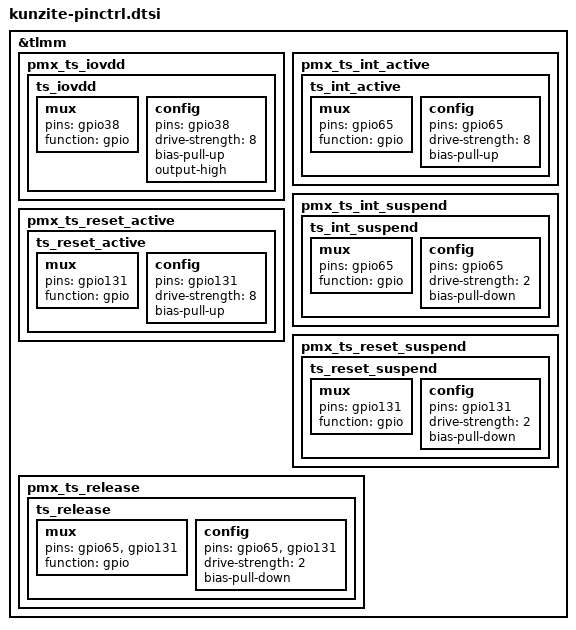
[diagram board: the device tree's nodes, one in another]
/* kunzite-pinctrl.dtsi */
&tlmm {
		/* touchscreen pins */
		pmx_ts_iovdd{
			ts_iovdd: ts_iovdd{
				mux {
					pins = "gpio38";
					function = "gpio";
				};

				config{
					pins = "gpio38";
					drive-strength = <8>;
					bias-pull-up;
					output-high;
				};
			};
		};

		pmx_ts_int_active {
			ts_int_active: ts_int_active {
				mux {
					pins = "gpio65";
					function = "gpio";
				};

				config {
					pins = "gpio65";
					drive-strength = <8>;
					bias-pull-up;
				};
			};
		};

		pmx_ts_int_suspend {
			ts_int_suspend: ts_int_suspend {
				mux {
					pins = "gpio65";
					function = "gpio";
				};

				config {
					pins = "gpio65";
					drive-strength = <2>;
					bias-pull-down;
				};
			};
		};

		pmx_ts_reset_active {
			ts_reset_active: ts_reset_active {
				mux {
					pins = "gpio131";
					function = "gpio";
				};

				config {
					pins = "gpio131";
					drive-strength = <8>;
					bias-pull-up;
				};
			};
		};

		pmx_ts_reset_suspend {
			ts_reset_suspend: ts_reset_suspend {
				mux {
					pins = "gpio131";
					function = "gpio";
				};

				config {
					pins = "gpio131";
					drive-strength = <2>;
					bias-pull-down;
				};
			};
		};

		pmx_ts_release {
			ts_release: ts_release {
				mux {
					pins = "gpio65", "gpio131";
					function = "gpio";
				};

				config {
					pins = "gpio65", "gpio131";
					drive-strength = <2>;
					bias-pull-down;
				};
			};
		};
};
